AUTOSAR XML (schema 4-2-2)
standard types defined: float32, uint16, uint8
package /DataTypes/Base
  base type float32_base: category=FIXED_LENGTH, base-type-size=32, base-type-encoding=IEEE754, native-declaration=float32
  base type uint16_base: category=FIXED_LENGTH, base-type-size=16, base-type-encoding=NONE, native-declaration=uint16
  base type uint8_base: category=FIXED_LENGTH, base-type-size=8, base-type-encoding=NONE, native-declaration=uint8
package /DataTypes/Implementation
  impl type Speed_T: category=VALUE, base-type=float32_base
  impl type Status_T: category=VALUE, base-type=uint16_base
package /DataTypes/Application
  app type Distance_T: category=VALUE
  unit Velocity_T_Unit: display-name=km/h
  app type Velocity_T: category=VALUE, compu {phys=raw*0.1; unit km/h}, range phys 0..400, unit=km/h
  app type Gear_T: category=VALUE, compu {0=PARK, 1=DRIVE}
  application array data type Samples_T: category=ARRAY
    element Element: category=VALUE, type=Velocity_T, array-size-semantics=FIXED-SIZE, max-number-of-elements=4
  application record data type Pose_T: category=STRUCTURE
    application record element x: category=VALUE, type=Distance_T
    application record element gear: category=VALUE, type=Gear_T
package /DataTypes/MappingSets
  data type mapping set PhysicalTypes
    data-type-maps:
      application-data-type=Distance_T, implementation-data-type=float32
      application-data-type=Velocity_T, implementation-data-type=Speed_T
package /PortInterfaces
  sender receiver interface IActuatorStatus
    data status: type=Status_T
  client server interface ICalibration
    operation SetOffset
      arg samples: type=Samples_T, direction=IN
      arg raw: type=uint8, direction=OUT, server-argument-impl-policy=USE-ARGUMENT-TYPE
  sender receiver interface IPose
    data pose: type=Pose_T
  sender receiver interface IVehicleSpeed
    data speed: type=Speed_T
package /ComponentTypes
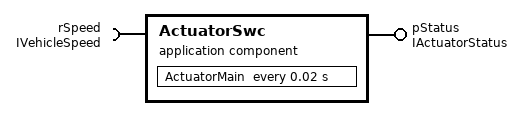
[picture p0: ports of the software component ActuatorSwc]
  application sw component type ActuatorSwc
    provide port pStatus: nonqueued-sender-com-spec=data-element=status, provided-interface=IActuatorStatus
    require port rSpeed: nonqueued-receiver-com-spec=data-element=speed, required-interface=IVehicleSpeed
    behavior ActuatorSwc_InternalBehavior: handle-termination-and-restart=NO-SUPPORT
      timing event TMT_ActuatorMain: start-on-event=ActuatorMain, period=0.02
      runnable ActuatorMain
  swc implementation ActuatorSwc_Implementation: behavior=ActuatorSwc_InternalBehavior
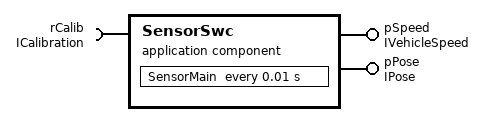
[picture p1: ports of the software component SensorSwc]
  application sw component type SensorSwc
    provide port pSpeed: nonqueued-sender-com-spec=data-element=speed, provided-interface=IVehicleSpeed
    provide port pPose: nonqueued-sender-com-spec=data-element=pose, provided-interface=IPose
    require port rCalib: client-com-spec=SetOffset, required-interface=ICalibration
    behavior SensorSwc_InternalBehavior: handle-termination-and-restart=NO-SUPPORT
      timing event TMT_SensorMain: start-on-event=SensorMain, period=0.01
      init event IT_SensorMain: start-on-event=SensorMain
      runnable SensorMain: minimum-start-interval=0.005
  swc implementation SensorSwc_Implementation: behavior=SensorSwc_InternalBehavior
  composition sw component type Root  # Root composition | The root every project owes; both components stand in it once.
    component SensorSwc: type=SensorSwc
    component ActuatorSwc: type=ActuatorSwc
    connect SensorSwc.pSpeed -> ActuatorSwc.rSpeed
